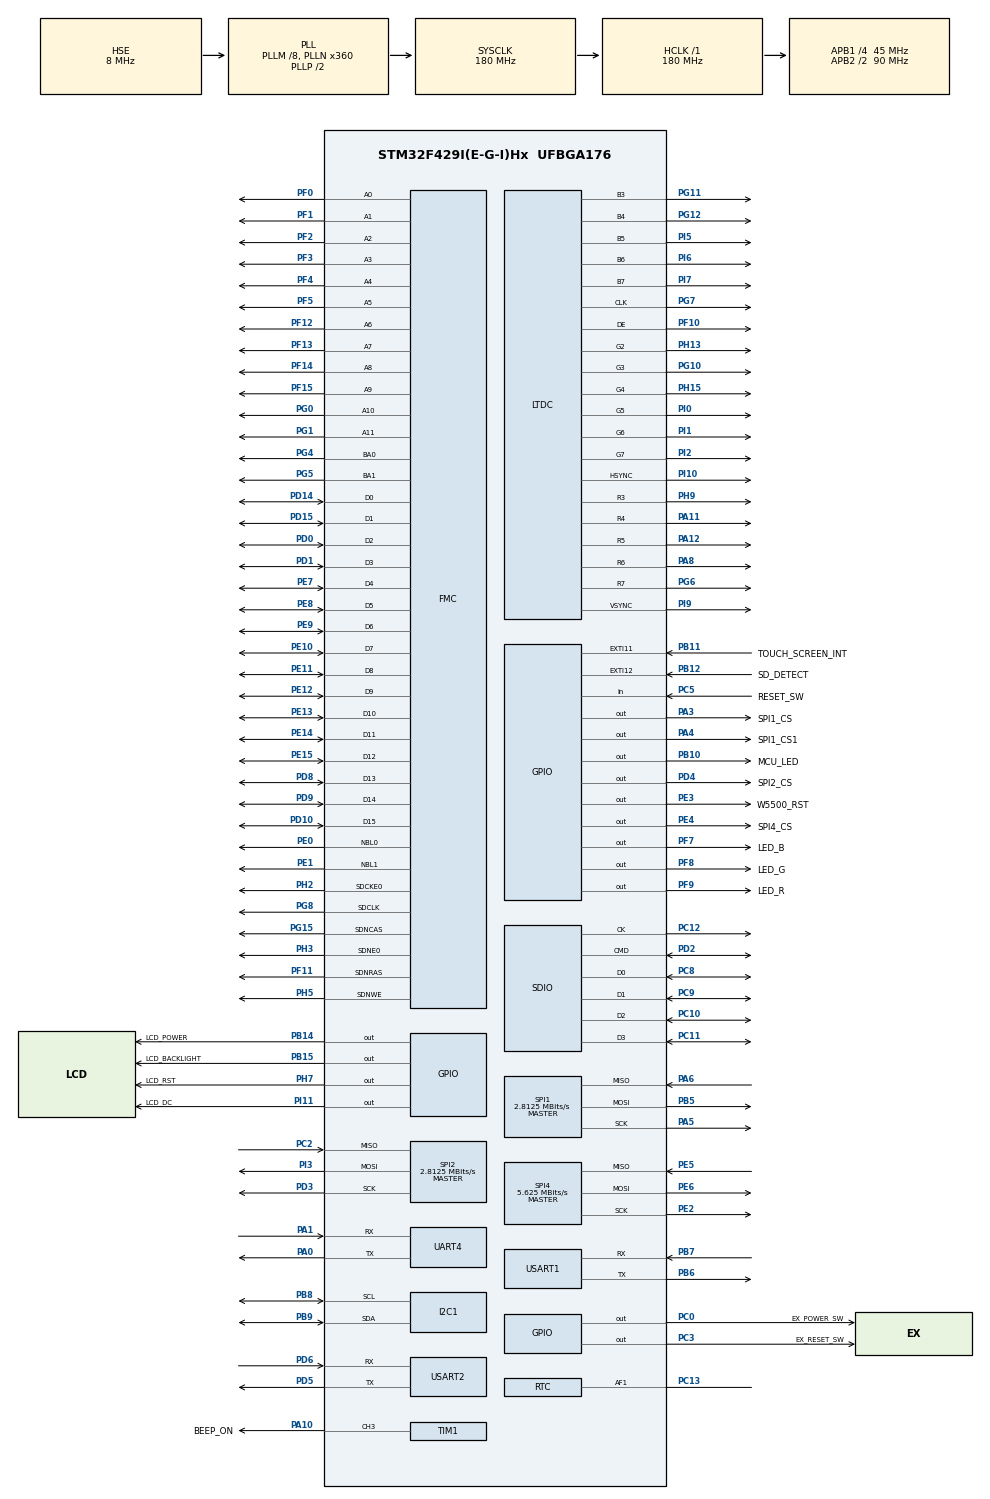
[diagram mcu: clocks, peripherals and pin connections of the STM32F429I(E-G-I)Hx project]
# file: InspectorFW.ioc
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DMA2D.ColorMode=DMA2D_OUTPUT_RGB565
FMC.CASLatency1=FMC_SDRAM_CAS_LATENCY_3
FMC.ExitSelfRefreshDelay1=7
FMC.LoadToActiveDelay1=2
FMC.RCDDelay1=2
FMC.RPDelay1=2
FMC.RPDelay2=2
FMC.ReadPipeDelay1=FMC_SDRAM_RPIPE_DELAY_1
FMC.ReadPipeDelay2=FMC_SDRAM_RPIPE_DELAY_1
FMC.RowCycleDelay1=7
FMC.RowCycleDelay2=7
FMC.SDClockPeriod1=FMC_SDRAM_CLOCK_PERIOD_2
FMC.SDClockPeriod2=FMC_SDRAM_CLOCK_PERIOD_2
FMC.SelfRefreshTime1=4
FMC.WriteRecoveryTime1=3
FREERTOS.Tasks01=System,16,256,System_Task,As weak,NULL,Dynamic,NULL,NULL;GUI_Task,24,8192,TouchGFX_Task,As weak,NULL,Dynamic,NULL,NULL
FREERTOS.configTOTAL_HEAP_SIZE=65536
FREERTOS.configUSE_NEWLIB_REENTRANT=1
LTDC.ActiveH=320
LTDC.ActiveW=240
LTDC.Alpha_L0=255
LTDC.Alpha_L1=255
LTDC.HBP=20
LTDC.HFP=10
LTDC.HSync=10
LTDC.ImageHeight_L0=320
LTDC.ImageHeight_L1=320
LTDC.ImageWidth_L0=240
LTDC.ImageWidth_L1=240
LTDC.Layers=0
LTDC.PixelFormat_L0=LTDC_PIXEL_FORMAT_RGB565
LTDC.VFP=4
LTDC.VSync=2
LTDC.WindowX1_L0=240
LTDC.WindowX1_L1=240
LTDC.WindowY1_L0=320
LTDC.WindowY1_L1=320
Mcu.Family=STM32F4
Mcu.Name=STM32F429I(E-G-I)Hx
Mcu.Package=UFBGA176
NVIC.DMA2D_IRQn=true\:5\:0\:false\:false\:true\:true\:true\:true\:true
NVIC.LTDC_IRQn=true\:5\:0\:false\:false\:true\:true\:true\:true\:true
NVIC.PriorityGroup=NVIC_PRIORITYGROUP_4
NVIC.SDIO_IRQn=true\:5\:0\:false\:false\:true\:true\:true\:true\:true
NVIC.TIM6_DAC_IRQn=true\:15\:0\:false\:false\:true\:false\:false\:true\:true
NVIC.TimeBase=TIM6_DAC_IRQn
NVIC.TimeBaseIP=TIM6
NVIC.UART4_IRQn=true\:5\:0\:false\:false\:true\:true\:true\:true\:true
NVIC.USART1_IRQn=true\:5\:0\:false\:false\:true\:true\:true\:true\:true
NVIC.USART2_IRQn=true\:5\:0\:false\:false\:true\:true\:true\:true\:true
PA0/WKUP.Mode=Asynchronous
PA0/WKUP.Signal=UART4_TX
PA1.Mode=Asynchronous
PA1.Signal=UART4_RX
PA10.GPIO_Label=BEEP_ON
PA10.Signal=S_TIM1_CH3
PA11.Mode=RGB565
PA11.Signal=LTDC_R4
PA12.Mode=RGB565
PA12.Signal=LTDC_R5
PA13.Mode=Serial_Wire
PA13.Signal=SYS_JTMS-SWDIO
PA14.Mode=Serial_Wire
PA14.Signal=SYS_JTCK-SWCLK
PA3.GPIO_Label=SPI1_CS
PA3.GPIO_Speed=GPIO_SPEED_FREQ_HIGH
PA3.PinState=GPIO_PIN_SET
PA3.Signal=GPIO_Output
PA4.GPIO_Label=SPI1_CS1
PA4.PinState=GPIO_PIN_SET
PA4.Signal=GPIO_Output
PA5.Mode=Full_Duplex_Master
PA5.Signal=SPI1_SCK
PA6.Mode=Full_Duplex_Master
PA6.Signal=SPI1_MISO
PA8.Mode=RGB565
PA8.Signal=LTDC_R6
PB10.GPIO_Label=MCU_LED
PB10.Signal=GPIO_Output
PB11.GPIO_Label=TOUCH_SCREEN_INT
PB11.Signal=GPXTI11
PB12.GPIO_Label=SD_DETECT
PB12.Signal=GPXTI12
PB14.GPIO_Label=LCD_POWER
PB14.Signal=GPIO_Output
PB15.GPIO_Label=LCD_BACKLIGHT
PB15.Signal=GPIO_Output
PB5.Mode=Full_Duplex_Master
PB5.Signal=SPI1_MOSI
PB6.Mode=Asynchronous
PB6.Signal=USART1_TX
PB7.Mode=Asynchronous
PB7.Signal=USART1_RX
PB8.Mode=I2C
PB8.Signal=I2C1_SCL
PB9.Mode=I2C
PB9.Signal=I2C1_SDA
PC0.GPIO_Label=EX_POWER_SW
PC0.Signal=GPIO_Output
PC10.Mode=SD_4_bits_Wide_bus
PC10.Signal=SDIO_D2
PC11.Mode=SD_4_bits_Wide_bus
PC11.Signal=SDIO_D3
PC12.Mode=SD_4_bits_Wide_bus
PC12.Signal=SDIO_CK
PC13.Mode=Calibration_1Hz
PC13.Signal=RTC_AF1
PC14/OSC32_IN.Mode=LSE-External-Oscillator
PC14/OSC32_IN.Signal=RCC_OSC32_IN
PC15/OSC32_OUT.Mode=LSE-External-Oscillator
PC15/OSC32_OUT.Signal=RCC_OSC32_OUT
PC2.Mode=Full_Duplex_Master
PC2.Signal=SPI2_MISO
PC3.GPIO_Label=EX_RESET_SW
PC3.Signal=GPIO_Output
PC5.GPIO_Label=RESET_SW
PC5.Signal=GPIO_Input
PC8.Mode=SD_4_bits_Wide_bus
PC8.Signal=SDIO_D0
PC9.Mode=SD_4_bits_Wide_bus
PC9.Signal=SDIO_D1
PD0.Signal=FMC_D2_DA2
PD1.Signal=FMC_D3_DA3
PD10.Signal=FMC_D15_DA15
PD14.Signal=FMC_D0_DA0
PD15.Signal=FMC_D1_DA1
PD2.Mode=SD_4_bits_Wide_bus
PD2.Signal=SDIO_CMD
PD3.Mode=Full_Duplex_Master
PD3.Signal=SPI2_SCK
PD4.GPIO_Label=SPI2_CS
PD4.GPIO_Speed=GPIO_SPEED_FREQ_HIGH
PD4.PinState=GPIO_PIN_SET
PD4.Signal=GPIO_Output
PD5.Mode=Asynchronous
PD5.Signal=USART2_TX
PD6.Mode=Asynchronous
PD6.Signal=USART2_RX
PD8.Signal=FMC_D13_DA13
PD9.Signal=FMC_D14_DA14
PE0.Signal=FMC_NBL0
PE1.Signal=FMC_NBL1
PE10.Signal=FMC_D7_DA7
PE11.Signal=FMC_D8_DA8
PE12.Signal=FMC_D9_DA9
PE13.Signal=FMC_D10_DA10
PE14.Signal=FMC_D11_DA11
PE15.Signal=FMC_D12_DA12
PE2.Mode=Full_Duplex_Master
PE2.Signal=SPI4_SCK
PE3.GPIO_Label=W5500_RST
PE3.Signal=GPIO_Output
PE4.GPIO_Label=SPI4_CS
PE4.GPIO_Speed=GPIO_SPEED_FREQ_HIGH
PE4.PinState=GPIO_PIN_SET
PE4.Signal=GPIO_Output
PE5.Mode=Full_Duplex_Master
PE5.Signal=SPI4_MISO
PE6.Mode=Full_Duplex_Master
PE6.Signal=SPI4_MOSI
PE7.Signal=FMC_D4_DA4
PE8.Signal=FMC_D5_DA5
PE9.Signal=FMC_D6_DA6
PF0.Signal=FMC_A0
PF1.Signal=FMC_A1
PF10.Mode=RGB565
PF10.Signal=LTDC_DE
PF11.Signal=FMC_SDNRAS
PF12.Signal=FMC_A6
PF13.Signal=FMC_A7
PF14.Signal=FMC_A8
PF15.Signal=FMC_A9
PF2.Signal=FMC_A2
PF3.Signal=FMC_A3
PF4.Signal=FMC_A4
PF5.Signal=FMC_A5
PF7.GPIO_Label=LED_B
PF7.Signal=GPIO_Output
PF8.GPIO_Label=LED_G
PF8.Signal=GPIO_Output
PF9.GPIO_Label=LED_R
PF9.Signal=GPIO_Output
PG0.Signal=FMC_A10
PG1.Signal=FMC_A11
PG10.Mode=RGB565
PG10.Signal=LTDC_G3
PG11.Mode=RGB565
PG11.Signal=LTDC_B3
PG12.Mode=RGB565
PG12.Signal=LTDC_B4
PG15.Signal=FMC_SDNCAS
PG4.Signal=FMC_A14_BA0
PG5.Signal=FMC_A15_BA1
PG6.Mode=RGB565
PG6.Signal=LTDC_R7
PG7.Mode=RGB565
PG7.Signal=LTDC_CLK
PG8.Signal=FMC_SDCLK
PH0/OSC_IN.Mode=HSE-External-Oscillator
PH0/OSC_IN.Signal=RCC_OSC_IN
PH1/OSC_OUT.Mode=HSE-External-Oscillator
PH1/OSC_OUT.Signal=RCC_OSC_OUT
PH13.Mode=RGB565
PH13.Signal=LTDC_G2
PH15.Mode=RGB565
PH15.Signal=LTDC_G4
PH2.Mode=SdramChipSelect1_1
PH2.Signal=FMC_SDCKE0
PH3.Mode=SdramChipSelect1_1
PH3.Signal=FMC_SDNE0
PH5.Signal=FMC_SDNWE
PH7.GPIO_Label=LCD_RST
PH7.Signal=GPIO_Output
PH9.Mode=RGB565
PH9.Signal=LTDC_R3
PI0.Mode=RGB565
PI0.Signal=LTDC_G5
PI1.Mode=RGB565
PI1.Signal=LTDC_G6
PI10.Mode=RGB565
PI10.Signal=LTDC_HSYNC
PI11.GPIO_Label=LCD_DC
PI11.GPIO_Speed=GPIO_SPEED_FREQ_MEDIUM
PI11.Signal=GPIO_Output
PI2.Mode=RGB565
PI2.Signal=LTDC_G7
PI3.Mode=Full_Duplex_Master
PI3.Signal=SPI2_MOSI
PI5.Mode=RGB565
PI5.Signal=LTDC_B5
PI6.Mode=RGB565
PI6.Signal=LTDC_B6
PI7.Mode=RGB565
PI7.Signal=LTDC_B7
PI9.Mode=RGB565
PI9.Signal=LTDC_VSYNC
ProjectManager.HeapSize=0xA00
ProjectManager.StackSize=0xA00
ProjectManager.TargetToolchain=STM32CubeIDE
RCC.48MHZClocksFreq_Value=45000000
RCC.AHBFreq_Value=180000000
RCC.APB1CLKDivider=RCC_HCLK_DIV4
RCC.APB1Freq_Value=45000000
RCC.APB1TimFreq_Value=90000000
RCC.APB2CLKDivider=RCC_HCLK_DIV2
RCC.APB2Freq_Value=90000000
RCC.APB2TimFreq_Value=180000000
RCC.CortexFreq_Value=180000000
RCC.HCLKFreq_Value=180000000
RCC.HSE_VALUE=8000000
RCC.HSI_VALUE=16000000
RCC.PLLM=8
RCC.PLLN=360
RCC.PLLQ=8
RCC.PLLSAIDivR=RCC_PLLSAIDIVR_8
RCC.PLLSAIN=192
RCC.PLLSAIR=4
RCC.PLLSourceVirtual=RCC_PLLSOURCE_HSE
RCC.PWR_Regulator_Voltage_Scale=PWR_REGULATOR_VOLTAGE_SCALE1
RCC.RCC_RTC_Clock_Source=RCC_RTCCLKSOURCE_LSE
RCC.RCC_RTC_Clock_SourceVirtual=RCC_RTCCLKSOURCE_LSE
RCC.SYSCLKFreq_VALUE=180000000
RCC.SYSCLKSource=RCC_SYSCLKSOURCE_PLLCLK
RCC.VCOOutputFreq_Value=360000000
SDIO.ClockDiv=2
SH.FMC_A0.0=FMC_A0,12b-sda1
SH.FMC_A1.0=FMC_A1,12b-sda1
SH.FMC_A10.0=FMC_A10,12b-sda1
SH.FMC_A11.0=FMC_A11,12b-sda1
SH.FMC_A14_BA0.0=FMC_BA0,FourSdramBanks1
SH.FMC_A15_BA1.0=FMC_BA1,FourSdramBanks1
SH.FMC_A2.0=FMC_A2,12b-sda1
SH.FMC_A3.0=FMC_A3,12b-sda1
SH.FMC_A4.0=FMC_A4,12b-sda1
SH.FMC_A5.0=FMC_A5,12b-sda1
SH.FMC_A6.0=FMC_A6,12b-sda1
SH.FMC_A7.0=FMC_A7,12b-sda1
SH.FMC_A8.0=FMC_A8,12b-sda1
SH.FMC_A9.0=FMC_A9,12b-sda1
SH.FMC_D0_DA0.0=FMC_D0,sd-16b-d1
SH.FMC_D10_DA10.0=FMC_D10,sd-16b-d1
SH.FMC_D11_DA11.0=FMC_D11,sd-16b-d1
SH.FMC_D12_DA12.0=FMC_D12,sd-16b-d1
SH.FMC_D13_DA13.0=FMC_D13,sd-16b-d1
SH.FMC_D14_DA14.0=FMC_D14,sd-16b-d1
SH.FMC_D15_DA15.0=FMC_D15,sd-16b-d1
SH.FMC_D1_DA1.0=FMC_D1,sd-16b-d1
SH.FMC_D2_DA2.0=FMC_D2,sd-16b-d1
SH.FMC_D3_DA3.0=FMC_D3,sd-16b-d1
SH.FMC_D4_DA4.0=FMC_D4,sd-16b-d1
SH.FMC_D5_DA5.0=FMC_D5,sd-16b-d1
SH.FMC_D6_DA6.0=FMC_D6,sd-16b-d1
SH.FMC_D7_DA7.0=FMC_D7,sd-16b-d1
SH.FMC_D8_DA8.0=FMC_D8,sd-16b-d1
SH.FMC_D9_DA9.0=FMC_D9,sd-16b-d1
SH.FMC_NBL0.0=FMC_NBL0,Sd2ByteEnable1
SH.FMC_NBL1.0=FMC_NBL1,Sd2ByteEnable1
SH.FMC_SDCLK.0=FMC_SDCLK,12b-sda1
SH.FMC_SDNCAS.0=FMC_SDNCAS,12b-sda1
SH.FMC_SDNRAS.0=FMC_SDNRAS,12b-sda1
SH.FMC_SDNWE.0=FMC_SDNWE,12b-sda1
SH.S_TIM1_CH3.0=TIM1_CH3,PWM Generation3 CH3
SPI1.BaudRatePrescaler=SPI_BAUDRATEPRESCALER_32
SPI1.CalculateBaudRate=2.8125 MBits/s
SPI1.Direction=SPI_DIRECTION_2LINES
SPI1.Mode=SPI_MODE_MASTER
SPI1.VirtualType=VM_MASTER
SPI2.BaudRatePrescaler=SPI_BAUDRATEPRESCALER_16
SPI2.CalculateBaudRate=2.8125 MBits/s
SPI2.Direction=SPI_DIRECTION_2LINES
SPI2.Mode=SPI_MODE_MASTER
SPI2.VirtualType=VM_MASTER
SPI4.BaudRatePrescaler=SPI_BAUDRATEPRESCALER_16
SPI4.CalculateBaudRate=5.625 MBits/s
SPI4.Direction=SPI_DIRECTION_2LINES
SPI4.Mode=SPI_MODE_MASTER
SPI4.VirtualType=VM_MASTER
STMicroelectronics.X-CUBE-TOUCHGFX.4.20.0.ApplicationCcGraphicsJjApplication=TouchGFXOoGenerator
STMicroelectronics.X-CUBE-TOUCHGFX.4.20.0.tgfx_buffering_strategy=Double
STMicroelectronics.X-CUBE-TOUCHGFX.4.20.0.tgfx_display_interface=disp_ltdc
STMicroelectronics.X-CUBE-TOUCHGFX.4.20.0.tgfx_hardware_accelerator=dma_2d
STMicroelectronics.X-CUBE-TOUCHGFX.4.20.0.tgfx_location=Allocate
STMicroelectronics.X-CUBE-TOUCHGFX.4.20.0.tgfx_vsync=vsync_ltdc
STMicroelectronics.X-CUBE-TOUCHGFX.4.20.0_IsPackSelfContextualization=true
TIM1.Channel-PWM\ Generation3\ CH3=TIM_CHANNEL_3
TIM1.Period=370
TIM1.Prescaler=180
TIM1.Pulse-PWM\ Generation3\ CH3=185
UART4.VirtualMode=Asynchronous
USART1.VirtualMode=VM_ASYNC
USART2.VirtualMode=VM_ASYNC
VP_CRC_VS_CRC.Mode=CRC_Activate
VP_DMA2D_VS_DMA2D.Mode=DMA2D_Activate
VP_FATFS_VS_SDIO.Mode=SDIO
VP_FREERTOS_VS_CMSIS_V2.Mode=CMSIS_V2
VP_RTC_VS_RTC_Activate.Mode=RTC_Enabled
VP_STMicroelectronics.X-CUBE-TOUCHGFX_VS_GraphicsJjApplication_4.20.0.Mode=GraphicsJjApplication
VP_SYS_VS_tim6.Mode=TIM6
board=custom

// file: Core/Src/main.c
/* USER CODE BEGIN Header */
/**
 ******************************************************************************
 * @file           : main.c
 * @brief          : Main program body
 ******************************************************************************
 * @attention
 *
 * Copyright (c) 2022 STMicroelectronics.
 * All rights reserved.
 *
 * This software is licensed under terms that can be found in the LICENSE file
 * in the root directory of this software component.
 * If no LICENSE file comes with this software, it is provided AS-IS.
 *
 ******************************************************************************
 */
/* USER CODE END Header */
#include "main.h"
#include "cmsis_os.h"
#include "crc.h"
#include "dma2d.h"
#include "fatfs.h"
#include "i2c.h"
#include "ltdc.h"
#include "rtc.h"
#include "sdio.h"
#include "spi.h"
#include "tim.h"
#include "usart.h"
#include "gpio.h"
#include "fmc.h"
#include "app_touchgfx.h"

void SystemClock_Config(void);
void MX_FREERTOS_Init(void);

int main(void)
{

  /* MCU Configuration--------------------------------------------------------*/

  /* Reset of all peripherals, Initializes the Flash interface and the Systick. */
  HAL_Init();

  /* Configure the system clock */
  SystemClock_Config();

  /* USER CODE BEGIN SysInit */
	SysParam_Init();
  /* USER CODE END SysInit */

  /* Initialize all configured peripherals */
  MX_GPIO_Init();
  MX_CRC_Init();
  MX_I2C1_Init();
  MX_SPI1_Init();
  MX_DMA2D_Init();
  MX_FMC_Init();
  MX_LTDC_Init();
  MX_USART2_UART_Init();
  MX_SPI2_Init();
  MX_SPI4_Init();
  MX_TIM1_Init();
  MX_SDIO_SD_Init();
  MX_UART4_Init();
  MX_USART1_UART_Init();
  MX_FATFS_Init();
  MX_RTC_Init();
  MX_TouchGFX_Init();
  /* Call PreOsInit function */
  MX_TouchGFX_PreOSInit();

  /* Init scheduler */
  osKernelInitialize();  /* Call init function for freertos objects (in freertos.c) */
  MX_FREERTOS_Init();

  /* Start scheduler */
  osKernelStart();

  /* We should never get here as control is now taken by the scheduler */
  /* Infinite loop */
	while (1) {

	}
}

void SystemClock_Config(void)
{
  RCC_OscInitTypeDef RCC_OscInitStruct = {0};
  RCC_ClkInitTypeDef RCC_ClkInitStruct = {0};

  /** Configure the main internal regulator output voltage
  */
  __HAL_RCC_PWR_CLK_ENABLE();
  __HAL_PWR_VOLTAGESCALING_CONFIG(PWR_REGULATOR_VOLTAGE_SCALE1);

  /** Initializes the RCC Oscillators according to the specified parameters
  * in the RCC_OscInitTypeDef structure.
  */
  RCC_OscInitStruct.OscillatorType = RCC_OSCILLATORTYPE_HSE|RCC_OSCILLATORTYPE_LSE;
  RCC_OscInitStruct.HSEState = RCC_HSE_ON;
  RCC_OscInitStruct.LSEState = RCC_LSE_ON;
  RCC_OscInitStruct.PLL.PLLState = RCC_PLL_ON;
  RCC_OscInitStruct.PLL.PLLSource = RCC_PLLSOURCE_HSE;
  RCC_OscInitStruct.PLL.PLLM = 8;
  RCC_OscInitStruct.PLL.PLLN = 360;
  RCC_OscInitStruct.PLL.PLLP = RCC_PLLP_DIV2;
  RCC_OscInitStruct.PLL.PLLQ = 8;
  if (HAL_RCC_OscConfig(&RCC_OscInitStruct) != HAL_OK)
  {
    Error_Handler();
  }

  /** Activate the Over-Drive mode
  */
  if (HAL_PWREx_EnableOverDrive() != HAL_OK)
  {
    Error_Handler();
  }

  /** Initializes the CPU, AHB and APB buses clocks
  */
  RCC_ClkInitStruct.ClockType = RCC_CLOCKTYPE_HCLK|RCC_CLOCKTYPE_SYSCLK
                              |RCC_CLOCKTYPE_PCLK1|RCC_CLOCKTYPE_PCLK2;
  RCC_ClkInitStruct.SYSCLKSource = RCC_SYSCLKSOURCE_PLLCLK;
  RCC_ClkInitStruct.AHBCLKDivider = RCC_SYSCLK_DIV1;
  RCC_ClkInitStruct.APB1CLKDivider = RCC_HCLK_DIV4;
  RCC_ClkInitStruct.APB2CLKDivider = RCC_HCLK_DIV2;

  if (HAL_RCC_ClockConfig(&RCC_ClkInitStruct, FLASH_LATENCY_5) != HAL_OK)
  {
    Error_Handler();
  }
}

void HAL_TIM_PeriodElapsedCallback(TIM_HandleTypeDef *htim)
{
  if (htim->Instance == TIM6) {
    HAL_IncTick();
  }
}

void Error_Handler(void)
{
	__disable_irq();
	while (1) {
	}
}

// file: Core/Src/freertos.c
/* USER CODE BEGIN Header */
/**
  ******************************************************************************
  * File Name          : freertos.c
  * Description        : Code for freertos applications
  ******************************************************************************
  * @attention
  *
  * Copyright (c) 2022 STMicroelectronics.
  * All rights reserved.
  *
  * This software is licensed under terms that can be found in the LICENSE file
  * in the root directory of this software component.
  * If no LICENSE file comes with this software, it is provided AS-IS.
  *
  ******************************************************************************
  */
/* USER CODE END Header */

#include "FreeRTOS.h"
#include "task.h"
#include "main.h"
#include "cmsis_os.h"

/* USER CODE BEGIN Includes */
#include "ModbusTask.h"
/* USER CODE END Includes */

/* Definitions for System */
osThreadId_t SystemHandle;
const osThreadAttr_t System_attributes = {
  .name = "System",
  .stack_size = 256 * 4,
  .priority = (osPriority_t) osPriorityBelowNormal,
};
/* Definitions for GUI_Task */
osThreadId_t GUI_TaskHandle;
const osThreadAttr_t GUI_Task_attributes = {
  .name = "GUI_Task",
  .stack_size = 8192 * 4,
  .priority = (osPriority_t) osPriorityNormal,
};

/* USER CODE BEGIN FunctionPrototypes */
/* Definitions for GuiTaskMBox */
osMessageQueueId_t GuiTaskMBoxHandle;
const osMessageQueueAttr_t GuiTaskMBox_attributes = {
  .name = "GuiTaskMBox"
};

extern void TouchGFX_Task(void *argument);
/* USER CODE END FunctionPrototypes */

void System_Task(void *argument);
void TouchGFX_Task(void *argument);

void MX_FREERTOS_Init(void); /* (MISRA C 2004 rule 8.1) */

void MX_FREERTOS_Init(void) {
  /* USER CODE BEGIN Init */
	Modbus_Task_Init();
  /* USER CODE END Init */

  /* USER CODE BEGIN RTOS_QUEUES */
  /* add queues, ... */
  GuiTaskMBoxHandle = osMessageQueueNew (16, sizeof(GuiMessage_t), &GuiTaskMBox_attributes);
  /* USER CODE END RTOS_QUEUES */

  /* Create the thread(s) */
  /* creation of System */
  SystemHandle = osThreadNew(System_Task, NULL, &System_attributes);

  /* creation of GUI_Task */
  GUI_TaskHandle = osThreadNew(TouchGFX_Task, NULL, &GUI_Task_attributes);

}

__weak void System_Task(void *argument)
{
  for(;;)
  {
    osDelay(1);
  }
}

__weak void TouchGFX_Task(void *argument)
{
  for(;;)
  {
    osDelay(1);
  }
}
